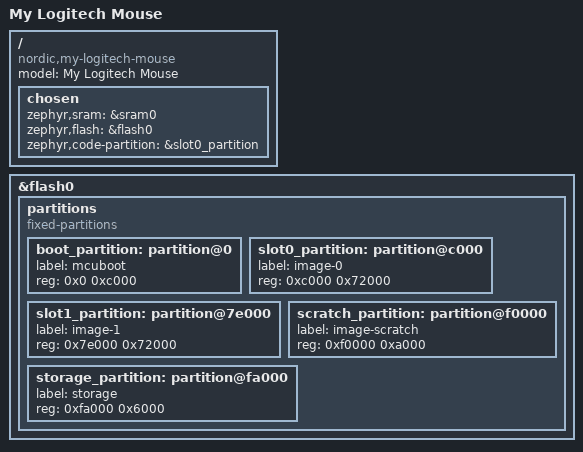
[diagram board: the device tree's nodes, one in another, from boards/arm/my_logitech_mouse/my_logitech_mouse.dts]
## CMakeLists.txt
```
#
# Copyright (c) 2018 Nordic Semiconductor
#
# SPDX-License-Identifier: LicenseRef-Nordic-5-Clause
#
cmake_minimum_required(VERSION 3.20.0)

find_package(Zephyr REQUIRED HINTS $ENV{ZEPHYR_BASE})
project(NONE)

FILE(GLOB app_sources src/*.c)
# NORDIC SDK APP START
target_sources(app PRIVATE src/main.cpp)
# NORDIC SDK APP END

zephyr_include_directories(src)

add_subdirectory(src/logimouse)
```

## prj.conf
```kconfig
#
# Copyright (c) 2019 Nordic Semiconductor ASA
#
# SPDX-License-Identifier: LicenseRef-Nordic-5-Clause
#
CONFIG_NCS_SAMPLES_DEFAULTS=y
CONFIG_ESB=y

# Include timer interrupt resources
CONFIG_COUNTER=y
CONFIG_NRFX_TIMER1=y

# Add support for C++
CONFIG_CPLUSPLUS=y
```

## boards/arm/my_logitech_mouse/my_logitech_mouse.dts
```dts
// Copyright (c) 2022 Nordic Semiconductor ASA
// SPDX-License-Identifier: Apache-2.0

/dts-v1/;
#include <nordic/nrf52840_qiaa.dtsi>

/ {
	model = "My Logitech Mouse";
	compatible = "nordic,my-logitech-mouse";

	chosen {
		zephyr,sram = &sram0;
		zephyr,flash = &flash0;
		zephyr,code-partition = &slot0_partition;
	};
};

&flash0 {
	partitions {
		compatible = "fixed-partitions";
		#address-cells = <1>;
		#size-cells = <1>;

		boot_partition: partition@0 {
			label = "mcuboot";
			reg = <0x0 0xc000>;
		};
		slot0_partition: partition@c000 {
			label = "image-0";
			reg = <0xc000 0x72000>;
		};
		slot1_partition: partition@7e000 {
			label = "image-1";
			reg = <0x7e000 0x72000>;
		};
		scratch_partition: partition@f0000 {
			label = "image-scratch";
			reg = <0xf0000 0xa000>;
		};
		storage_partition: partition@fa000 {
			label = "storage";
			reg = <0xfa000 0x6000>;
		};
	};
};
```

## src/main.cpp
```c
/*
 * Copyright (c) 2018 Nordic Semiconductor ASA
 *
 * SPDX-License-Identifier: LicenseRef-Nordic-5-Clause
 */

// #include <drivers/gpio.h>
#include <zephyr.h>
#include <logging/log.h>
#include "interrupt_timer.h"
#include "radio_controls.h"
#include "radio_unifying.h"
// #include <zephyr/types.h>
 
LOG_MODULE_REGISTER(esb_prx, CONFIG_ESB_PRX_APP_LOG_LEVEL); // what is this? 

void main(void) {
	Interrupt isr; // initialize logimouse
	isr.timer_init(); // initialize timer

	// create radio object
	RadioControls radio;

	while(1) {
		__WFE(); // wake from event (esb event or counter event)
		// transmit pairing packet 1 and log the response
		// log pairing packet
		LOG_DBG("Pairing packet 1 byte 0: 0x%02x", RadioUnifying::pairing_packet_1[0]);
		k_sleep(K_MSEC(100)); // sleep for 100 ms

	}

	return;
}
```
